AUTOSAR XML (schema 4-2-2)
package /ComponentTypes
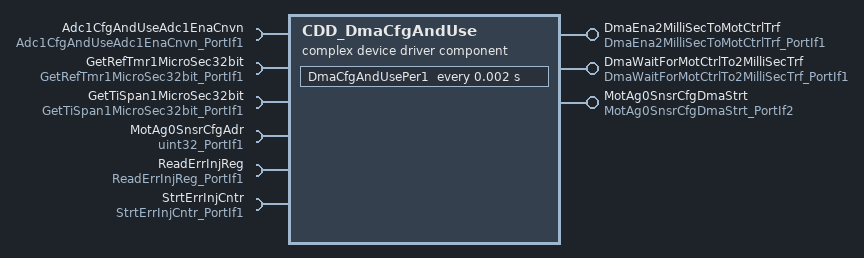
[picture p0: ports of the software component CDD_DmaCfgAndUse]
  complex device driver sw component type CDD_DmaCfgAndUse
    provide port DmaEna2MilliSecToMotCtrlTrf: server-com-spec{operation=Oper, queue-length=1}, provided-interface=DmaEna2MilliSecToMotCtrlTrf_PortIf1
    provide port DmaWaitForMotCtrlTo2MilliSecTrf: server-com-spec{operation=Oper, queue-length=1}, provided-interface=DmaWaitForMotCtrlTo2MilliSecTrf_PortIf1
    provide port MotAg0SnsrCfgDmaStrt: server-com-spec{operation=Oper, queue-length=1}, provided-interface=MotAg0SnsrCfgDmaStrt_PortIf2
    6 x require port:
      Adc1CfgAndUseAdc1EnaCnvn: client-com-spec=Oper, required-interface=Adc1CfgAndUseAdc1EnaCnvn_PortIf1
      GetRefTmr1MicroSec32bit: client-com-spec=Oper, required-interface=GetRefTmr1MicroSec32bit_PortIf1
      GetTiSpan1MicroSec32bit: client-com-spec=Oper, required-interface=GetTiSpan1MicroSec32bit_PortIf1
      MotAg0SnsrCfgAdr: nonqueued-receiver-com-spec{data-element=Val, filter=data-filter-type=ALWAYS, init-value=0}, required-interface=uint32_PortIf1
      ReadErrInjReg: client-com-spec=Oper, required-interface=ReadErrInjReg_PortIf1
      StrtErrInjCntr: client-com-spec=Oper, required-interface=StrtErrInjCntr_PortIf1
    behavior CDD_DmaCfgAndUse_InternalBehavior: data-type-mapping=Nexteer
      ar-typed-per-instance-memorys:
        9 x data, all with sw-calibration-access=READ-ONLY, type=uint32:
          d2MilliSecAdcActDmaTrfTi
          DmaCfgAndUse2MilliSecAdcMaxDmaTrfTi
          DmaCfgAndUse2MilliSecAdcStrtTi
          MotAg0ReadPtrRst
          MotAg0SnsrCfgAdrStord
          MotAg0TrsmStrt
          MotAg1ReadPtrRst
          MotAg1SnsrCfgAdrStord
          MotAg1TrsmStrt
      init event CDD_DmaCfgAndUse_InitEvent: start-on-event=DmaCfgAndUseInit1
      timing event TMT_DmaCfgAndUsePer1: start-on-event=DmaCfgAndUsePer1, period=0.002
      operation invoked event OIT_DmaEna2MilliSecToMotCtrlTrf_Oper_DmaEna2MilliSecToMotCtrlTrf_Oper: start-on-event=DmaEna2MilliSecToMotCtrlTrf_Oper, operation=DmaEna2MilliSecToMotCtrlTrf.Oper
      operation invoked event OIT_DmaWaitForMotCtrlTo2MilliSecTrf_Oper_DmaWaitForMotCtrlTo2MilliSecTrf_Oper: start-on-event=DmaWaitForMotCtrlTo2MilliSecTrf_Oper, operation=DmaWaitForMotCtrlTo2MilliSecTrf.Oper
      operation invoked event OIT_MotAg0SnsrCfgDmaStrt_Oper_MotAg0SnsrCfgDmaStrt_Oper: start-on-event=MotAg0SnsrCfgDmaStrt_Oper, operation=MotAg0SnsrCfgDmaStrt.Oper
      port-api-options:
        enable-take-address=false, error-handling=NO-TRANSFORMER-ERROR-HANDLING, indirect-api=false, port=Adc1CfgAndUseAdc1EnaCnvn
        enable-take-address=false, error-handling=NO-TRANSFORMER-ERROR-HANDLING, indirect-api=false, port=DmaEna2MilliSecToMotCtrlTrf
        enable-take-address=false, error-handling=NO-TRANSFORMER-ERROR-HANDLING, indirect-api=false, port=DmaWaitForMotCtrlTo2MilliSecTrf
        enable-take-address=false, error-handling=NO-TRANSFORMER-ERROR-HANDLING, indirect-api=false, port=GetRefTmr1MicroSec32bit
        enable-take-address=false, error-handling=NO-TRANSFORMER-ERROR-HANDLING, indirect-api=false, port=GetTiSpan1MicroSec32bit
        enable-take-address=false, error-handling=NO-TRANSFORMER-ERROR-HANDLING, indirect-api=false, port=MotAg0SnsrCfgAdr
        enable-take-address=false, error-handling=NO-TRANSFORMER-ERROR-HANDLING, indirect-api=false, port=MotAg0SnsrCfgDmaStrt
        enable-take-address=false, error-handling=NO-TRANSFORMER-ERROR-HANDLING, indirect-api=false, port=ReadErrInjReg
        enable-take-address=false, error-handling=NO-TRANSFORMER-ERROR-HANDLING, indirect-api=false, port=StrtErrInjCntr
      5 x runnable:
        DmaCfgAndUseInit1
          data-receive-point-by-arguments:
            access REC_MotAg0SnsrCfgAdr_Val: accessed-variable=MotAg0SnsrCfgAdr.Val
        DmaCfgAndUsePer1
          sync call SC_Adc1CfgAndUseAdc1EnaCnvn_Oper: operation=Adc1CfgAndUseAdc1EnaCnvn.Oper, timeout=0
          sync call SC_GetRefTmr1MicroSec32bit_Oper: operation=GetRefTmr1MicroSec32bit.Oper, timeout=0
        DmaEna2MilliSecToMotCtrlTrf_Oper
          sync call SC_ReadErrInjReg_Oper: operation=ReadErrInjReg.Oper, timeout=0
          sync call SC_StrtErrInjCntr_Oper: operation=StrtErrInjCntr.Oper, timeout=0
        DmaWaitForMotCtrlTo2MilliSecTrf_Oper
          sync call SC_GetTiSpan1MicroSec32bit_Oper: operation=GetTiSpan1MicroSec32bit.Oper, timeout=0
        MotAg0SnsrCfgDmaStrt_Oper
  swc implementation CDD_DmaCfgAndUse_Implementation: behavior=CDD_DmaCfgAndUse_InternalBehavior
    code-descriptors:
      code Default: artifact-descriptors=autosar-engineering-object={short-label=Default, category=SWSRC}
